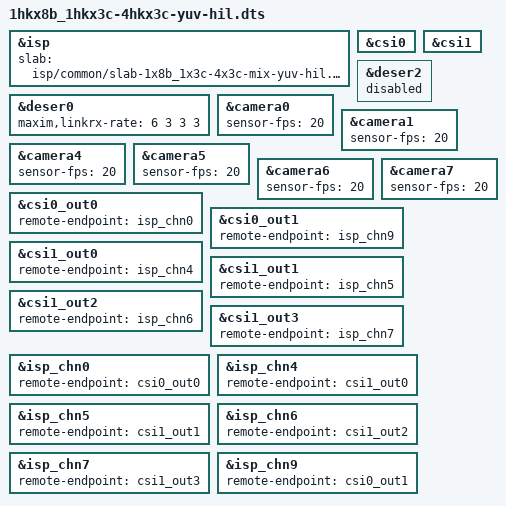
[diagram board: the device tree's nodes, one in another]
/dts-v1/;
/plugin/;

#include "base-isp.dtsi"
#include "base-csi-deser-camera.dtsi"
#include "base-desers-3max96724.dtsi"

&isp {
	slab = "isp/common/slab-1x8b_1x3c-4x3c-mix-yuv-hil.bin";
};

&csi0 {
	status = "okay";
};
&csi1 {
	status = "okay";
};

&deser0 {
	maxim,linkrx-rate = <6 3 3 3>;
};
&deser2 {
	status = "disabled";
};

&camera0 {
	#include "../cameras/ox08b_yuv_hk_hil.dtsi"
	sensor-fps = <20>;
	status = "okay";
};
&camera1 {
	#include "../cameras/ox3c_yuv_hk_hil.dtsi"
	sensor-fps = <20>;
	status = "okay";
};
&camera4 {
	#include "../cameras/ox3c_yuv_hk_hil.dtsi"
	sensor-fps = <20>;
	status = "okay";
};
&camera5 {
	#include "../cameras/ox3c_yuv_hk_hil.dtsi"
	sensor-fps = <20>;
	status = "okay";
};
&camera6 {
	#include "../cameras/ox3c_yuv_hk_hil.dtsi"
	sensor-fps = <20>;
	status = "okay";
};
&camera7 {
	#include "../cameras/ox3c_yuv_hk_hil.dtsi"
	sensor-fps = <20>;
	status = "okay";
};


&csi0_out0 {
	remote-endpoint = <&isp_chn0>;
};
&csi0_out1 {
	remote-endpoint = <&isp_chn9>;
};

&csi1_out0 {
	remote-endpoint = <&isp_chn4>;
};
&csi1_out1 {
	remote-endpoint = <&isp_chn5>;
};
&csi1_out2 {
	remote-endpoint = <&isp_chn6>;
};
&csi1_out3 {
	remote-endpoint = <&isp_chn7>;
};



&isp_chn0 {
	remote-endpoint = <&csi0_out0>;
};

&isp_chn4 {
	remote-endpoint = <&csi1_out0>;
};
&isp_chn5 {
	remote-endpoint = <&csi1_out1>;
};
&isp_chn6 {
	remote-endpoint = <&csi1_out2>;
};
&isp_chn7 {
	remote-endpoint = <&csi1_out3>;
};

&isp_chn9 {
	remote-endpoint = <&csi0_out1>;
};

